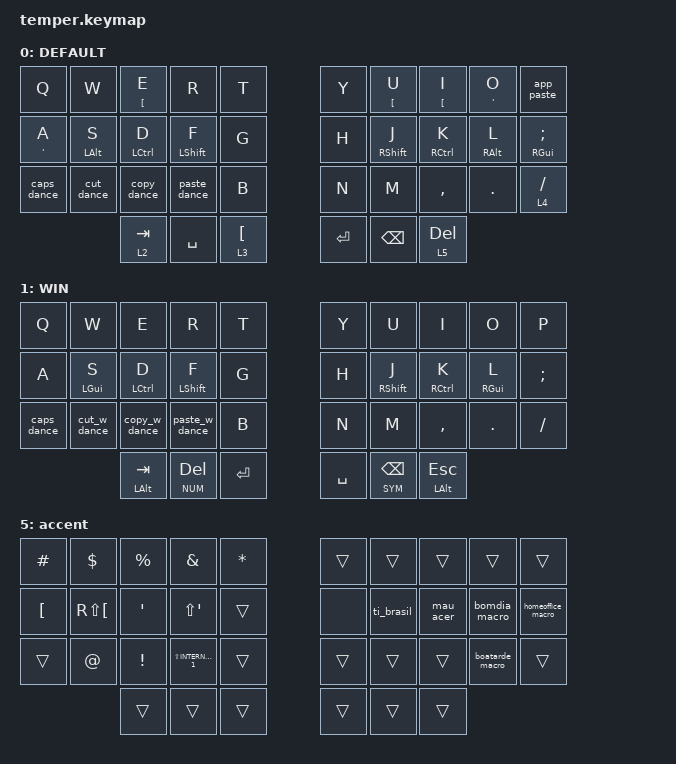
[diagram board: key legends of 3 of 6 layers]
/*
 * Copyright (c) 2020 The ZMK Contributors
 *
 * SPDX-License-Identifier: MIT
 */

#include <dt-bindings/zmk/reset.h>
#include <behaviors.dtsi>
#include <dt-bindings/zmk/bt.h>
#include <dt-bindings/zmk/keys.h>

#define DEFAULT 0
#define WIN 1
#define NUM 2
#define SYM 3
#define FUNC 4
#define ______ &trans

&mt {
    tapping-term-ms = <200>;
    flavor = "tap-preferred";
};

/ {
    conditional_layers {
        compatible = "zmk,conditional-layers";

        tri_layer {
            if-layers = <NUM SYM>;
            then-layer = <FUNC>;
        };
    };

    behaviors {
        // Home row mods

        hm: homerow_mods {
            compatible = "zmk,behavior-hold-tap";
            #binding-cells = <2>;
            tapping-term-ms = <200>;
            quick-tap-ms = <0>;
            flavor = "tap-preferred";
            bindings = <&kp>, <&kp>;
        };

        // Tap dance single tap = C double tap = gui+c

        copy_dance: tapdance_copy {
            compatible = "zmk,behavior-tap-dance";
            #binding-cells = <0>;
            tapping-term-ms = <250>;
            bindings = <&kp C>, <&kp RC(C)>;
        };

        copy_w_dance: tapdancew_copy {
            compatible = "zmk,behavior-tap-dance";
            #binding-cells = <0>;
            tapping-term-ms = <250>;
            bindings = <&kp C>, <&kp LC(C)>;
        };

        // Tap dance single tap = V double tap = gui+v

        paste_dance: tabdance_paste {
            compatible = "zmk,behavior-tap-dance";
            #binding-cells = <0>;
            tapping-term-ms = <250>;
            bindings = <&kp V>, <&kp RC(V)>;
        };

        paste_w_dance: tabdancew_paste {
            compatible = "zmk,behavior-tap-dance";
            #binding-cells = <0>;
            tapping-term-ms = <250>;
            bindings = <&kp V>, <&kp LC(V)>;
        };

        // Tap dance single tap = . double tap = SPACE

        dot_spc: dot_space {
            compatible = "zmk,behavior-tap-dance";
            #binding-cells = <0>;
            tapping-term-ms = <250>;
            bindings = <&kp DOT>, <&kp SPACE>;
        };

        // Tap dance single tap = Z double tap = CAPS LOCK

        caps_dance: tapdance_caps {
            compatible = "zmk,behavior-tap-dance";
            #binding-cells = <0>;
            tapping-term-ms = <250>;
            bindings = <&kp Z>, <&kp CAPS>;
        };

        // Tap dance single tap = X double tap = gui+x

        cut_dance: tapdance_cut {
            compatible = "zmk,behavior-tap-dance";
            #binding-cells = <0>;
            tapping-term-ms = <250>;
            bindings = <&kp X>, <&kp RC(X)>;
        };

        cut_w_dance: tapdancew_cut {
            compatible = "zmk,behavior-tap-dance";
            #binding-cells = <0>;
            tapping-term-ms = <250>;
            bindings = <&kp X>, <&kp LC(X)>;
        };

        // Tap dance single tap = P double tap = gui+shift+v

        app_paste: app_paste {
            compatible = "zmk,behavior-tap-dance";
            #binding-cells = <0>;
            tapping-term-ms = <250>;
            bindings = <&kp P>, <&kp RC(LS(V))>;
        };

        // Tap dance single tap = H double tap = Raycast seach (CMD + space)

        search_dance: tapdance_search {
            compatible = "zmk,behavior-tap-dance";
            #binding-cells = <0>;
            tapping-term-ms = <180>;
            bindings = <&kp H>, <&kp LG(SPACE)>;
        };

        // Enable hyper key when tapped

        tp: tap-preferred {
            compatible = "zmk,behavior-hold-tap";
            #binding-cells = <2>;
            tapping-term-ms = <150>;
            quick-tap-ms = <0>;
            flavor = "tap-preferred";
            bindings = <&kp>, <&kp>;
        };

        slash_comment: slash_comment {
            compatible = "zmk,behavior-tap-dance";
            label = "SLASH_COMMENT";
            #binding-cells = <0>;
            bindings = <&kp INTERNATIONAL_1>, <&kp RC(INTERNATIONAL_1)>;

            tapping-term-ms = <250>;
        };
    };

    /*                KEY POSITIONS
     ╭────────────────────╮ ╭────────────────────╮
     │  0   1   2   3   4 │ │  5   6   7   8   9 │
     │ 10  11  12  13  14 │ │ 15  16  17  18  19 │
     │ 20  21  22  23  24 │ │ 25  26  27  28  29 │
     ╰───────╮ 30  31  32 │ │ 33  34  35╭────────╯
             ╰────────────╯ ╰───────────╯            */

    combos {
        compatible = "zmk,combos";

        // Combo to type < > and move cursor left

        lt_gt_combo {
            timeout-ms = <50>;
            key-positions = <11 12>;
            layers = <0>;
            bindings = <&dq_macro>;
        };

        // Combo to type { } and move cursor left

        lb_rb_combo {
            timeout-ms = <50>;
            key-positions = <3 4>;
            layers = <0>;
            bindings = <&lb_rb_macro>;
        };

        // Combo to type ( ) and move cursor left

        lp_rp_combo {
            timeout-ms = <50>;
            key-positions = <13 14>;
            layers = <0>;
            bindings = <&lp_rp_macro>;
        };

        // Combo to type [ ] and move cursor left

        ls_rs_combo {
            timeout-ms = <50>;
            key-positions = <24 23>;
            layers = <0>;
            bindings = <&ls_rs_macro>;
        };

        // Combo to press the middle mouse button
        // Combo to go Next
        // Combo to go Previous

        sq_combo {
            bindings = <&sq_macro>;
            key-positions = <1 2>;
            timeout-ms = <50>;
            layers = <0>;
        };
    };

    macros {
        // Macro to exit vim: ESC : W Q

        vim_wq: vim_quit {
            compatible = "zmk,behavior-macro";
            #binding-cells = <0>;
            bindings = <&macro_tap>, <&kp ESC &kp COLON &kp W &kp Q &kp ENTER>;
        };

        // Macro to exit vim: ESC : Q !

        vim_q: vim_quit_force {
            compatible = "zmk,behavior-macro";
            #binding-cells = <0>;
            bindings =
                <&macro_tap>,
                <&kp ESC &kp COLON &kp Q &kp EXCL &kp ENTER>;
        };

        // Macro to type < > and move cursor left

        lt_gt_macro: lt_gt_macro_with_cursor {
            compatible = "zmk,behavior-macro";
            #binding-cells = <0>;
            bindings = <&macro_tap>, <&kp LT &kp GT &kp LEFT>;
        };

        // Macro to type { } and move cursor left

        lb_rb_macro: lb_rb_macro_with_cursor {
            compatible = "zmk,behavior-macro";
            #binding-cells = <0>;
            bindings =
                <&macro_tap>,
                <&kp LS(RIGHT_BRACE) &kp LS(BACKSLASH) &kp LEFT>;
        };

        // Macro to type ( ) and move cursor left

        lp_rp_macro: lp_rp_macro_with_cursor {
            compatible = "zmk,behavior-macro";
            #binding-cells = <0>;
            bindings = <&macro_tap>, <&kp LS(N9) &kp LS(N0) &kp LEFT>;
        };

        // Macro to type [ ] and move cursor left

        ls_rs_macro: ls_rs_macro_with_cursor {
            compatible = "zmk,behavior-macro";
            #binding-cells = <0>;
            bindings = <&macro_tap>, <&kp RIGHT_BRACKET &kp BACKSLASH &kp LEFT>;
        };

        // Macro to open homerow app (LGUI+LCTRL+LSHFT) 

        homeapp: homeapp {
            compatible = "zmk,behavior-macro";
            #binding-cells = <0>;
            bindings =
                <&macro_press>,
                <&kp LGUI &kp LCTRL &kp LSHFT>,
                <&macro_release>,
                <&kp LSHFT &kp LCTRL &kp LGUI>;
        };

        // Macro to type "" and move cursor left

        dq_macro: dq_macro_with_cursor {
            compatible = "zmk,behavior-macro";
            #binding-cells = <0>;
            bindings = <&macro_tap>, <&kp LS(GRAVE) &kp LS(GRAVE) &kp LEFT>;
        };

        // Macro to type euro marke

        ti_brasil: ti_brasil {
            compatible = "zmk,behavior-macro";
            #binding-cells = <0>;
            bindings = <&kp T &kp I &kp DOT &kp B &kp R &kp A &kp S &kp I &kp L &kp AT &kp A &kp C &kp E &kp R &kp DOT &kp C &kp O &kp M &none>;
            label = "TI_BRASIL";
        };

        mau_acer: mau_acer {
            compatible = "zmk,behavior-macro";
            #binding-cells = <0>;
            bindings = <&kp C &kp DOT &kp M &kp A &kp U &kp R &kp I &kp C &kp I &kp O &kp DOT &kp R &kp O &kp D &kp R &kp I &kp G &kp U &kp E &kp S &kp AT &kp A &kp C &kp E &kp R &kp DOT &kp C &kp O &kp M &none>;
            label = "MAU_ACER";
        };

        sq_macro: sq_macro_cursor {
            compatible = "zmk,behavior-macro";
            #binding-cells = <0>;
            bindings = <&macro_tap>, <&kp GRAVE &kp GRAVE &kp LEFT>;
        };

        bomdia_macro: bomdia_macro {
            compatible = "zmk,behavior-macro";
            #binding-cells = <0>;
            bindings = <&kp LS(B) &kp O &kp M &kp SPACE &kp D &kp I &kp A &kp EXCL &kp SPACE &none>;
            label = "BOMDIA_MACRO";
        };

        homeoffice_macro: homeoffice_macro {
            compatible = "zmk,behavior-macro";
            #binding-cells = <0>;
            bindings = <&kp LS(H) &kp O &kp M &kp E &kp SPACE &kp O &kp F &kp F &kp I &kp C &kp E &none>;
            label = "HOMEOFFICE_MACRO";
        };

        boatarde_macro: boatarde_macro {
            compatible = "zmk,behavior-macro";
            #binding-cells = <0>;
            bindings = <&kp LS(B) &kp O &kp A &kp SPACE &kp T &kp A &kp R &kp D &kp E &kp EXCLAMATION &kp SPACE &none>;
            label = "BOATARDE_MACRO";
        };

        ctrl_alt_del_macro: ctrl_alt_del_macro {
            compatible = "zmk,behavior-macro";
            #binding-cells = <0>;
            bindings =
                <&macro_press>,
                <&kp LCTRL &kp LEFT_ALT &kp DELETE>,
                <&macro_release>,
                <&kp LCTRL &kp LEFT_ALT &kp DEL>;

            label = "CTRL_ALT_DEL_MACRO";
        };
    };

    keymap {
        compatible = "zmk,keymap";

        default_layer {
            label = "DEFAULT";
            bindings = <
&kp Q             &kp W           &mt LEFT_BRACKET E  &kp R         &kp T               &kp Y      &mt LEFT_BRACKET U  &mt LEFT_BRACKET I  &mt APOS O       &app_paste
&mt APOSTROPHE A  &hm LEFT_ALT S  &hm LCTRL D         &hm LSHFT F   &kp G               &kp H      &hm RSHFT J         &hm RCTRL K         &hm RIGHT_ALT L  &hm RIGHT_GUI SEMI
&caps_dance       &cut_dance      &copy_dance         &paste_dance  &kp B               &kp N      &kp M               &kp COMMA           &kp DOT          &lt 4 SLASH
                                  &lt 2 TAB           &kp SPACE     &lt 3 LEFT_BRACKET  &kp ENTER  &kp BACKSPACE       &lt 5 DELETE
            >;
        };

        windows_layer {
            label = "WIN";
            bindings = <
&kp Q        &kp W         &kp E          &kp R           &kp T      &kp Y      &kp U         &kp I         &kp O       &kp P
&kp A        &hm LGUI S    &hm LCTRL D    &hm LSHFT F     &kp G      &kp H      &hm RSHFT J   &hm RCTRL K   &hm RGUI L  &kp SEMI
&caps_dance  &cut_w_dance  &copy_w_dance  &paste_w_dance  &kp B      &kp N      &kp M         &kp COMMA     &kp DOT     &kp FSLH
                           &tp LALT TAB   &lt NUM DEL     &kp ENTER  &kp SPACE  &lt SYM BSPC  &tp LALT ESC
            >;
        };

        num_layer {
            label = "NUM";
            bindings = <
&kp LEFT_PARENTHESIS  &kp RIGHT_PARENTHESIS  &kp COMMA  &kp PERIOD  &kp PERCENT  &none       &mt F7 N7        &mt F8 N8        &mt F9 N9        &none
&kp INTERNATIONAL_1   &kp ASTRK              &kp MINUS  &kp PLUS    &kp SPACE    &none       &mt F4 NUMBER_4  &mt F5 N5        &mt F6 NUMBER_6  &kp F12
&none                 &none                  &none      &none       &kp EQUAL    &mt F10 N0  &mt F1 NUMBER_1  &mt F2 NUMBER_2  &mt F3 NUMBER_3  &kp F11
                                             &trans     &trans      &trans
            >;
        };

        sym_layer {
            label = "SYM";
            bindings = <
&kp GRAVE        &kp LS(NUMBER_6)     &kp LS(MINUS)   &kp LS(RIGHT_BRACE)  &kp LS(BACKSLASH)  &none  &kp HOME        &kp UP_ARROW  &kp END     &kp PAGE_UP
&kp LS(GRAVE)    &kp EQUAL            &kp MINUS       &kp LS(N9)           &kp LS(N0)         &none  &kp LEFT_ARROW  &kp DOWN      &kp RIGHT   &kp PAGE_DOWN
&kp NON_US_BSLH  &kp LS(NON_US_BSLH)  &slash_comment  &kp RIGHT_BRACKET    &kp BACKSLASH      &none  &kp TAB         &kp ESCAPE    &kp INSERT  &none
            >;
        };

        func_layer {
            label = "FUNC";
            bindings = <
&bt BT_CLR           &bt BT_NXT  &bt BT_PRV    &bootloader   &sys_reset    &sys_reset  &bootloader  &none  &none  &none
&none                &none       &bt BT_SEL 0  &bt BT_SEL 1  &bt BT_SEL 2  &kp LNLCK   &none        &none  &none  &tog WIN
&ctrl_alt_del_macro  &none       &none         &none         &none         &none       &none        &none  &none  &none
            >;
        };

        accent {
            bindings = <
&kp HASH          &kp DOLLAR            &kp PERCENT       &kp AMPS                 &kp STAR  &trans  &trans      &trans     &trans           &trans
&kp LEFT_BRACKET  &kp RS(LEFT_BRACKET)  &kp SINGLE_QUOTE  &kp LS(SINGLE_QUOTE)     &trans    &none   &ti_brasil  &mau_acer  &bomdia_macro    &homeoffice_macro
&trans            &kp AT_SIGN           &kp EXCLAMATION   &kp LS(INTERNATIONAL_1)  &trans    &trans  &trans      &trans     &boatarde_macro  &trans
                                        &trans            &trans                   &trans    &trans  &trans      &trans
            >;
        };
    };
};
